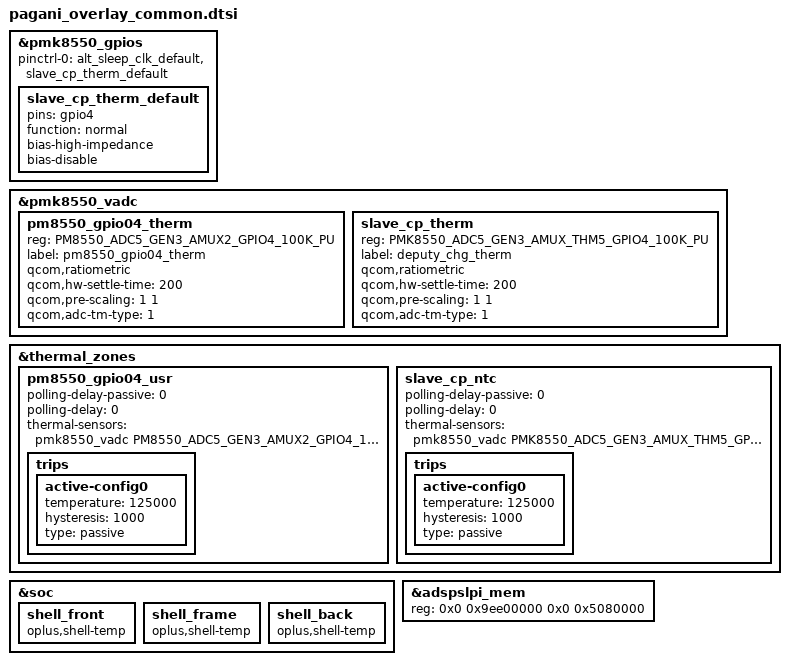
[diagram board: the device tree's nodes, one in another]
&pmk8550_gpios {
    pinctrl-0 = <&alt_sleep_clk_default>, <&slave_cp_therm_default>;
    pinctrl-names = "default";
    slave_cp_therm_default: slave_cp_therm_default {
        pins = "gpio4";
        function = "normal";
        bias-high-impedance;
        bias-disable;
    };
};

&pmk8550_vadc {
    pm8550_gpio04_therm {
        reg = <PM8550_ADC5_GEN3_AMUX2_GPIO4_100K_PU>;
        label = "pm8550_gpio04_therm";
        qcom,ratiometric;
        qcom,hw-settle-time = <200>;
        qcom,pre-scaling = <1 1>;
        qcom,adc-tm-type = <1>;
    };

    slave_cp_therm {
        reg = <PMK8550_ADC5_GEN3_AMUX_THM5_GPIO4_100K_PU>;
        label = "deputy_chg_therm";
        qcom,ratiometric;
        qcom,hw-settle-time = <200>;
        qcom,pre-scaling = <1 1>;
        qcom,adc-tm-type = <1>;
    };
};

&thermal_zones {
    pm8550_gpio04_usr {
        polling-delay-passive = <0>;
        polling-delay = <0>;
        thermal-sensors = <&pmk8550_vadc PM8550_ADC5_GEN3_AMUX2_GPIO4_100K_PU>;
        trips {
            active-config0 {
                temperature = <125000>;
                hysteresis = <1000>;
                type = "passive";
            };
        };
    };

    slave_cp_ntc {
        polling-delay-passive = <0>;
        polling-delay = <0>;
        thermal-sensors = <&pmk8550_vadc PMK8550_ADC5_GEN3_AMUX_THM5_GPIO4_100K_PU>;
        trips {
            active-config0 {
                temperature = <125000>;
                hysteresis = <1000>;
                type = "passive";
            };
        };
    };
};

&soc {
    //#ifdef OPLUS_FEATURE_THERMAL_HORAE
    shell_front {
        compatible = "oplus,shell-temp";
    };

    shell_frame {
        compatible = "oplus,shell-temp";
    };

    shell_back {
        compatible = "oplus,shell-temp";
    };
    //#endif /* OPLUS_FEATURE_THERMAL_HORAE */
};

&adspslpi_mem {
	reg = <0x0 0x9ee00000 0x0 0x5080000>;
};
